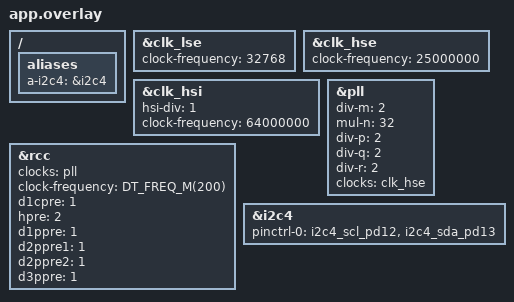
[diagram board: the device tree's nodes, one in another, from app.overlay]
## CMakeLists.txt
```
# SPDX-License-Identifier: Apache-2.0

cmake_minimum_required(VERSION 3.20.0)

find_package(Zephyr REQUIRED HINTS $ENV{ZEPHYR_BASE})
project(hello_world)


include (${CMAKE_SOURCE_DIR}/cmake/functions.cmake)
set(PRE_CONFIGURE_FILE "${CMAKE_CURRENT_SOURCE_DIR}/cmake/git.h.in")
set(POST_CONFIGURE_FILE "${CMAKE_CURRENT_SOURCE_DIR}/git.h")
include (${CMAKE_CURRENT_SOURCE_DIR}/cmake/git_watcher.cmake)
set (CMAKE_CXX_STANDARD 17)


set (PROJ_TOP ${CMAKE_CURRENT_SOURCE_DIR}/../..)

target_sources(app PRIVATE 
	src/uart.c	
	src/main.cpp
	src/pcb9685.cpp
	src/servo.cpp
	src/motor.cpp
	${PROJ_TOP}/robot/comm_protocol/protocol-v1/ProtocolStateMachine.cpp
	${PROJ_TOP}/robot/hal/zephyr/uart_zephyr.cpp
)


target_include_directories(app PRIVATE
	${PROJ_TOP}/comm_protocol/
	${PROJ_TOP}/robot/hal
	${PROJ_TOP}/
	${PROJ_TOP}/robot/comm_protocol/
	${PROJ_TOP}/robot/
	${PROJECT_BINARY_DIR}
	)
```

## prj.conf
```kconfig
# nothing here
#CONFIG_SYS_CLOCK_HW_CYCLES_PER_SEC=192000000
CONFIG_DEBUG=y
CONFIG_STDOUT_CONSOLE=y
CONFIG_NO_OPTIMIZATIONS=y
CONFIG_SERIAL=y
CONFIG_CPLUSPLUS=y
CONFIG_NEWLIB_LIBC_NANO=n
CONFIG_LIB_CPLUSPLUS=y
CONFIG_STDOUT_CONSOLE=y
CONFIG_UART_INTERRUPT_DRIVEN=y
CONFIG_I2C=y
CONFIG_LOG=y
CONFIG_MAIN_STACK_SIZE=8092
```

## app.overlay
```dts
/ {
	aliases {
		a-i2c4  = &i2c4;
	};

};

&clk_lse {
	status = "okay";
	clock-frequency = <32768>;
};

&clk_hse {
	status = "okay";
	clock-frequency = <25000000>;
};

&clk_hsi {
	hsi-div = <1>;
	status = "okay";
	clock-frequency = <64000000>;
};

&pll {
	div-m = <2>;
	mul-n = <32>;
	div-p = <2>;
	div-q = <2>;
	div-r = <2>;
	clocks = <&clk_hse>;
	status = "okay";
};

&rcc {
	clocks = <&pll>;
	clock-frequency = <DT_FREQ_M(200)>;

	d1cpre = <1>;
         hpre = <2>;
         d1ppre = <1>;
         d2ppre1 = <1>;
         d2ppre2 = <1>;
         d3ppre = <1>;
};

&i2c4 {
	pinctrl-0 = <&i2c4_scl_pd12 &i2c4_sda_pd13>;
	pinctrl-names = "default";
	status = "okay";
	/*clock-frequency = <I2C_BITRATE_FAST>;*/
};
```

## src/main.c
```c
/*
 * Copyright (c) 2012-2014 Wind River Systems, Inc.
 *
 * SPDX-License-Identifier: Apache-2.0
 */

#include <zephyr/kernel.h>
#include <zephyr/device.h>
#include <zephyr/devicetree.h>
#include <zephyr/drivers/uart.h>

#include <zephyr/kernel.h>
#include <zephyr/device.h>
#include <zephyr/drivers/gpio.h>
#include <zephyr/sys/printk.h>
#include <zephyr/sys/__assert.h>
#include <string.h>


//#include "robot.h"


/* size of stack area used by each thread */
#define STACKSIZE 1024

/* scheduling priority used by each thread */
#define PRIORITY 7



/* UART device name */
#define UART_DEV_NAME usart3

/* UART buffer */
#define UART_BUF_SIZE 64
static uint8_t uart_buffer[UART_BUF_SIZE];

/* UART device structure */
static const struct  device *uart_dev;

/* UART ISR callback */
static void uart_isr(const struct device *dev, void *user_data)
{
	// ARG_UNUSED(user_data);
	uint8_t recv_data;
	int rx_err;

	while (uart_irq_update(dev) && uart_irq_is_pending(dev)) {
		if (uart_irq_rx_ready(dev)) {
			rx_err = uart_fifo_read(dev, &recv_data, 1);
			if (rx_err == 0) {
				// Process received data
				// ...
			}
		}
	}
}



#define UART_DEVICE_NODE DT_CHOSEN(zephyr_shell_uart)
#define UART_NODE2 DT_ALIAS(single_line_uart2)
#define UART_NODE2a DT_CHOSEN(zephyr_console)

const struct device *const sl_uart1 ;//= DEVICE_DT_GET(UART_NODE2);
const struct device *const sl_uart2 = DEVICE_DT_GET(UART_NODE2a);



// static const struct device *const uart_dev = DEVICE_DT_GET(UART_DEVICE_NODE);


/* Initialize and configure UART */
static int uart_init(void)
{
	uart_dev = DEVICE_DT_GET(UART_NODE2a);

	//   uart_dev = device_get_binding("usart3");
	if (!uart_dev) {
		printk("Failed to get UART device\n");
		return -ENODEV;
	}

	/* Configure UART */
	const struct uart_config uart_cfg = {
		.baudrate = 115200,
		.parity = UART_CFG_PARITY_NONE,
		.stop_bits = UART_CFG_STOP_BITS_1,
		.data_bits = UART_CFG_DATA_BITS_8,
		.flow_ctrl = UART_CFG_FLOW_CTRL_NONE
	};

	int ret = uart_configure(uart_dev, &uart_cfg);
	if (ret != 0) {
		printk("Failed to configure UART: %d\n", ret);
		return ret;
	}

	/* Register UART ISR callback */
	uart_irq_callback_set(uart_dev, uart_isr);

	/* Enable UART interrupt */
	uart_irq_rx_enable(uart_dev);

	printk("UART initialized\n");
	return 0;
}

int main(void)
{
	int ret;

	printk("Zephyr USART Example\n");

	/* Initialize UART */
	ret = uart_init();
	if (ret != 0) {
		printk("UART initialization failed\n");
		return;
	}

	unsigned char recv;
#if 0
	if (/*!device_is_ready(sl_uart1) || */!device_is_ready(sl_uart2)) {
		printk("uart devices not ready\n");
		return 0;
	}
#endif
	char c='a';
	while (true) {
		//uart_poll_out(sl_uart2, c);
		//c++;
		//if (c=='z')
		//	 c='a';
		/* give the uarts some time to get the data through */
		//k_sleep(K_MSEC(50));

		int ret = uart_poll_in(sl_uart2, &c);

		if (ret < 0) {
			//printk("Receiving failed. Error: %d", ret);
		} else {
			uart_poll_out(sl_uart2, c);	
			//	k_sleep(K_MSEC(50));

			//		printk("Received %c\n", recv);
		}

	}
	return 0;

}
```

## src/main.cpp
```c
/*
 * Copyright (c) 2012-2014 Wind River Systems, Inc.
 *
 * SPDX-License-Identifier: Apache-2.0
 */
#include <string.h>
#include <memory>

#include <zephyr/devicetree.h>
#include <zephyr/kernel.h>
#include <zephyr/device.h>
#include <zephyr/drivers/gpio.h>
#include <zephyr/sys/printk.h>
#include <zephyr/sys/__assert.h>
#include <zephyr/drivers/uart.h>
#include <zephyr/drivers/i2c.h>
#include "zephyr/uart_zephyr.h"

#include "protocol-v1/ProtocolStateMachine.h"
#include "protocol-v1/ProtoclDataStructures.h"
#include "HandleUartMsg.h"
#include "robot.h"
#include "pcb9685.h"
#include "motor.h"


/* size of stack area used by each thread */
#define STACKSIZE 8096

/* scheduling priority used by each thread */
#define PRIORITY 7



# if DT_NODE_HAS_STATUS(DT_ALIAS(a_i2c4), okay)
#	define I2C_DEV_NODE	DT_ALIAS(a_i2c4)
# else
#	error "Please set the correct I2C device"
# endif


//const struct device *const sl_uart1 ;//= DEVICE_DT_GET(UART_NODE2);
#define UART_NODE2 DT_CHOSEN(zephyr_console)
const struct device *const sl_uart2 = DEVICE_DT_GET(UART_NODE2);

//uint32_t i2c_cfg = I2C_SPEED_SET(I2C_SPEED_STANDARD) | I2C_MODE_CONTROLLER;
//const struct device *const i2c_dev = DEVICE_DT_GET(I2C_DEV_NODE);
const struct device * const i2c_dev = DEVICE_DT_GET(DT_NODELABEL(i2c4));
//const struct device * i2c_dev = 
// static const struct device *const uart_dev = DEVICE_DT_GET(UART_DEVICE_NODE);


K_MSGQ_DEFINE(sevo_msgq, sizeof(Payload::ServoParams), 16, 4);



pcb9685 * g_pwm = new pcb9685(i2c_dev);
Motor  * g_motor = new Motor(g_pwm, &sevo_msgq);


int main(void)
{
	std::cout << "begin c++ app"<<std::endl;		
	printk("Zephyr USART Example\n");

	while (1) {
		k_sleep(K_MSEC(2000));		
	}


	return 0;

}



double map_angle (int min_pwm, int max_pwm, int angle) {
	double min_ang=0;
	double max_ang=180;
	double pwm = (max_pwm-min_pwm)/(max_ang-min_ang) * angle + min_pwm;
	pwm = pwm /  1000000; // move to uq
	return pwm;	     
}
void servo_command_listenr(void *p1,void *p2, void *p3)
{
	Simple::Payload::ServoParams  servoParams;
	Motor * motor = * ( (Motor **) p1); 

	printk("servo_command_listenr\n");

	motor->setup();
	while (1) {
		if (k_msgq_get(&sevo_msgq, &servoParams, K_FOREVER) == 0) {
			for (int i = 0; i <16; i++) {
				double c = map_angle(servoParams.min_pwm, servoParams.max_pwm , servoParams.angle[i]);
				if (servoParams.update_bit & (1<<i))
					motor->setServoPulse(i,c);
			}
		}
	}
	k_sleep(K_MSEC(2000));			
}

K_THREAD_DEFINE(servo_command_listenr_id, STACKSIZE, servo_command_listenr, &g_motor, NULL, NULL, PRIORITY, 0, 0);



void message_in_listenr(void *p1,void *p2, void *p3)
{
	Motor * motor = *( (Motor **) p1); 
	printk("message_in_listenr\n");

	auto uart = Hal::GetUartZephyr(sl_uart2);
	uart->Open();
	auto p  =  std::shared_ptr<Simple::HandleUartMsg>(new Simple::HandleUartMsg(uart, motor) );
	std::shared_ptr<IProtocolParser> parser = std::shared_ptr<Simple::ProtocolStateMachine> ( new Simple::ProtocolStateMachine  (uart, p));


#if 0
	auto login =  [] () ->void{

	};	
	login();
#endif

	while (1) {
		parser->Parse();
	}
}

K_THREAD_DEFINE(message_in_listenr_id, STACKSIZE, message_in_listenr, &g_motor, NULL, NULL, PRIORITY, 0, 0);
```

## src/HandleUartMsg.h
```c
/*
 * =====================================================================================
 *
 *       Filename:  protocol.h
 *
 *    Description:  
 *
 *        Version:  1.0
 *        Created:  11/11/2022 03:14:53 PM
 *       Revision:  none
 *       Compiler:  gcc
 *
 *        Company:  Israel
 *
 * =====================================================================================
 */

#ifndef PROTOCOL_H
#define PROTOCOL_H 
#include <string>
#include <memory>
#include <vector>

#include <cstring>
#include <type_traits>
#include <utility>

#include "IProtocolParser.h"

#include "protocol-v1/ProtoclDataStructures.h"
#include "protocol-v1/SensorDataParser.h"
#include "protocol-v1/messages.h"
#include "protocol-v1/IHandleUartMsg.h"
#include "common/logger.h"

#include "motor.h"
namespace Simple {

	class HandleUartMsg: public IHandleUartMsg {
		public:
			HandleUartMsg(std::shared_ptr<Hal::IUart> uart, Motor *motor) : m_uart(uart) {
				m_motor = motor;
			}
			void NewData(const MsgToParse &msg) override {
				switch (msg.cmd) {

					case CmdId::GetDeviceInfo:
						{

							DeviceInfo deviceInfo;
							auto msg = deviceInfo();
							///msg->data.hw_version [0] = 1;
							int n = m_uart->Send(msg->buffer,msg->size()); 
							(void)n;

							break;
						}
					case CmdId::SetMotorAngle:
						{	
							Payload::ServoParams *di = (Payload::ServoParams*)(msg.data.buffer);	
							if (m_motor->pushMessage(*di) == 0) {
								Ack ack;
								auto res_msg = ack();
								int n = m_uart->Send(res_msg->buffer,res_msg->size()); 
								(void)n;
							} else {
								NotAck ack;
								auto res_msg = ack();
								int n = m_uart->Send(res_msg->buffer,res_msg->size()); 
								(void)n;
							}
							break;

						}

				}

			};
			void Wrongdata() override {
			};
		private:
			std::shared_ptr<Hal::IUart> m_uart;			
			Motor * m_motor;


	};





}



#endif
```

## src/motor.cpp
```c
/*
 * =====================================================================================
 *
 *       Filename:  motor.cpp
 *
 *    Description:  
 *
 *        Version:  1.0
 *        Created:  07/11/2023 10:58:14 PM
 *       Revision:  none
 *       Compiler:  gcc
 *
 *         Author:  Yair Gadelov (yg), yair.gadelov@gmail.com
 *        Company:  Israel
 *
 * =====================================================================================
 */

#include "motor.h"
#define SERVOMIN  150 // This is the 'minimum' pulse length count (out of 4096)
#define SERVOMAX  600 // This is the 'maximum' pulse length count (out of 4096)
#define USMIN  600 // This is the rounded 'minimum' microsecond length based on the minimum pulse of 150
#define USMAX  2400 // This is the rounded 'maximum' microsecond length based on the maximum pulse of 600
#define SERVO_FREQ 50 // Analog servos run at ~50 Hz updates
#define delay(x) k_sleep(K_MSEC(x))


void Motor::setServoPulse( uint8_t n, double pulse) {
  double pulselength;
  
  pulselength = 1000000;   // 1,000,000 us per second
  pulselength /= SERVO_FREQ;   // Analog servos run at ~60 Hz updates
  //Serial.print(pulselength); Serial.println(" us per period"); 
  pulselength /= 4096;  // 12 bits of resolution
 // Serial.print(pulselength); Serial.println(" us per bit"); 
  pulse *= 1000000;  // convert input seconds to us
  pulse /= pulselength;
//  Serial.println(pulse);
  m_pwm->setPWM(n, 0, pulse);
}


void Motor::setup() {
  m_pwm->begin();
  /*
   * In theory the internal oscillator (clock) is 25MHz but it really isn't
   * that precise. You can 'calibrate' this by tweaking this number until
   * you get the PWM update frequency you're expecting!
   * The int.osc. for the PCA9685 chip is a range between about 23-27MHz and
   * is used for calculating things like writeMicroseconds()
   * Analog servos run at ~50 Hz updates, It is importaint to use an
   * oscilloscope in setting the int.osc frequency for the I2C PCA9685 chip.
   * 1) Attach the oscilloscope to one of the PWM signal pins and ground on
   *    the I2C PCA9685 chip you are setting the value for.
   * 2) Adjust setOscillatorFrequency() until the PWM update frequency is the
   *    expected value (50Hz for most ESCs)
   * Setting the value here is specific to each individual I2C PCA9685 chip and
   * affects the calculations for the PWM update frequency. 
   * Failure to correctly set the int.osc value will cause unexpected PWM results
   */
//  pwm->setOscillatorFrequency(27000000);
  m_pwm->setPWMFreq(SERVO_FREQ);  // Analog servos run at ~50 Hz updates
}
```

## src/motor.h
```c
/*
 * =====================================================================================
 *
 *       Filename:  motor.h
 *
 *    Description:  
 *
 *        Version:  1.0
 *        Created:  07/11/2023 10:58:26 PM
 *       Revision:  none
 *       Compiler:  gcc
 *
 *         Author:  Yair Gadelov (yg), yair.gadelov@gmail.com
 *        Company:  Israel
 *
 * =====================================================================================
 */

#ifndef MOTOR_H
#define MOTOR_H 
#include "pcb9685.h"
#include <zephyr/kernel.h>
#include "protocol-v1/ProtoclDataStructures.h"

class Motor {
	public:
		Motor(pcb9685 * pwm, k_msgq * msgq) : m_pwm(pwm) {
			m_msgq = msgq;
		}
		void setServoPulse(uint8_t n, double pulse);
		int pushMessage(Simple::Payload::ServoParams  & motorAngle) {
			int e = k_msgq_put(m_msgq, &motorAngle, K_NO_WAIT);
			return e;
		}
		void setup();
		
	private:
		pcb9685  * m_pwm;
		k_msgq * m_msgq;
};
#endif
```

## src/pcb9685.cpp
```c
/*
 * =====================================================================================
 *
 *       Filename:  pcb9685.h
 *
 *    Description:  driver for pca9685. Taken from arduino imelemnation here:
 *    https://github.com/adafruit/Adafruit-PWM-Servo-Driver-Library/blob/master/Adafruit_PWMServoDriver.cpp#L222
 *
 *        Version:  1.0
 *        Created:  07/02/2023 12:23:34 PM
 *       Revision:  none
 *       Compiler:  gcc
 *
 *         Author:  Yair Gadelov (yg), yair.gadelov@gmail.com
 *        Company:  Israel
 *
 * =====================================================================================
 */

#include "pcb9685.h"
#include <zephyr/kernel.h>
#include <memory>
#include <iostream>
#define delay(x) k_sleep(K_MSEC(x))

#define ENABLE_DEBUG_OUTPUT




/*!
 *  @brief  Setups the I2C interface and hardware
 *  @param  prescale
 *          Sets External Clock (Optional)
 *  @return true if successful, otherwise false
 */
bool pcb9685::begin(uint8_t prescale) {
  reset();
  if (prescale) {
    setExtClk(prescale);
  } else {
    // set a default frequency
    setPWMFreq(1000);
  }
  // set the default internal frequency
  setOscillatorFrequency(FREQUENCY_OSCILLATOR);

  return true;
}

/*!
 *  @brief  Sends a reset command to the PCA9685 chip over I2C
 */
void pcb9685::reset() {
  write8(PCA9685_MODE1, MODE1_RESTART);
  delay(10);
}

/*!
 *  @brief  Puts board into sleep mode
 */
void pcb9685::sleep() {
  uint8_t awake = read8(PCA9685_MODE1);
  uint8_t sleep = awake | MODE1_SLEEP; // set sleep bit high
  write8(PCA9685_MODE1, sleep);
  delay(5); // wait until cycle ends for sleep to be active
}

/*!
 *  @brief  Wakes board from sleep
 */
void pcb9685::wakeup() {
  uint8_t sleep = read8(PCA9685_MODE1);
  uint8_t wakeup = sleep & ~MODE1_SLEEP; // set sleep bit low
  write8(PCA9685_MODE1, wakeup);
}

/*!
 *  @brief  Sets EXTCLK pin to use the external clock
 *  @param  prescale
 *          Configures the prescale value to be used by the external clock
 */
void pcb9685::setExtClk(uint8_t prescale) {
  uint8_t oldmode = read8(PCA9685_MODE1);
  uint8_t newmode = (oldmode & ~MODE1_RESTART) | MODE1_SLEEP; // sleep
  write8(PCA9685_MODE1, newmode); // go to sleep, turn off internal oscillator

  // This sets both the SLEEP and EXTCLK bits of the MODE1 register to switch to
  // use the external clock.
  write8(PCA9685_MODE1, (newmode |= MODE1_EXTCLK));

  write8(PCA9685_PRESCALE, prescale); // set the prescaler

  delay(5);
  // clear the SLEEP bit to start
  write8(PCA9685_MODE1, (newmode & ~MODE1_SLEEP) | MODE1_RESTART | MODE1_AI);

#ifdef ENABLE_DEBUG_OUTPUT
  //printk("Mode now 0x");
//  printk("%d %x \n",read8(PCA9685_MODE1), HEX);
#endif
}

/*!
 *  @brief  Sets the PWM frequency for the entire chip, up to ~1.6 KHz
 *  @param  freq Floating point frequency that we will attempt to match
 */
void pcb9685::setPWMFreq(float freq) {
#ifdef ENABLE_DEBUG_OUTPUT
  printk("Attempting to set freq ");
  printk("%lf \n",freq);
#endif
  // Range output modulation frequency is dependant on oscillator
  if (freq < 1)
    freq = 1;
  if (freq > 3500)
    freq = 3500; // Datasheet limit is 3052=50MHz/(4*4096)

  float prescaleval = ((_oscillator_freq / (freq * 4096.0)) + 0.5) - 1;
  if (prescaleval < PCA9685_PRESCALE_MIN)
    prescaleval = PCA9685_PRESCALE_MIN;
  if (prescaleval > PCA9685_PRESCALE_MAX)
    prescaleval = PCA9685_PRESCALE_MAX;
  uint8_t prescale = (uint8_t)prescaleval;

#ifdef ENABLE_DEBUG_OUTPUT
  printk("Final pre-scale: ");
  printk("%d \n",prescale);
#endif

  uint8_t oldmode = read8(PCA9685_MODE1);
  uint8_t newmode = (oldmode & ~MODE1_RESTART) | MODE1_SLEEP; // sleep
  write8(PCA9685_MODE1, newmode);                             // go to sleep
  write8(PCA9685_PRESCALE, prescale); // set the prescaler
  write8(PCA9685_MODE1, oldmode);
  delay(5);
  // This sets the MODE1 register to turn on auto increment.
  write8(PCA9685_MODE1, oldmode | MODE1_RESTART | MODE1_AI);

#ifdef ENABLE_DEBUG_OUTPUT
 // printk("Mode now 0x");
  //printk("%d %x\n",read8(PCA9685_MODE1), HEX);
#endif
}

/*!
 *  @brief  Sets the output mode of the PCA9685 to either
 *  open drain or push pull / totempole.
 *  Warning: LEDs with integrated zener diodes should
 *  only be driven in open drain mode.
 *  @param  totempole Totempole if true, open drain if false.
 */
void pcb9685::setOutputMode(bool totempole) {
  uint8_t oldmode = read8(PCA9685_MODE2);
  uint8_t newmode;
  if (totempole) {
    newmode = oldmode | MODE2_OUTDRV;
  } else {
    newmode = oldmode & ~MODE2_OUTDRV;
  }
  write8(PCA9685_MODE2, newmode);
#ifdef ENABLE_DEBUG_OUTPUT
  printk("Setting output mode: ");
  printk(totempole ? "totempole" : "open drain");
  printk(" by setting MODE2 to ");
  printk("%d ",newmode);
#endif
}

/*!
 *  @brief  Reads set Prescale from PCA9685
 *  @return prescale value
 */
uint8_t pcb9685::readPrescale(void) {
  return read8(PCA9685_PRESCALE);
}

/*!
 *  @brief  Gets the PWM output of one of the PCA9685 pins
 *  @param  num One of the PWM output pins, from 0 to 15
 *  @param  off If true, returns PWM OFF value, otherwise PWM ON
 *  @return requested PWM output value
 */
uint16_t pcb9685::getPWM(uint8_t num, bool off) {
  uint8_t buffer[2] = {uint8_t(PCA9685_LED0_ON_L + 4 * num), 0};
  if (off)
    buffer[0] += 2;
  	i2c_write_read (m_i2c_dev, PCA9685_I2C_ADDRESS,buffer, 1 , buffer, 2);
	//  i2c_dev->write_then_read(buffer, 1, buffer, 2);
  return uint16_t(buffer[0]) | (uint16_t(buffer[1]) << 8);
}

/*!
 *  @brief  Sets the PWM output of one of the PCA9685 pins
 *  @param  num One of the PWM output pins, from 0 to 15
 *  @param  on At what point in the 4096-part cycle to turn the PWM output ON
 *  @param  off At what point in the 4096-part cycle to turn the PWM output OFF
 *  @return result from endTransmission
 */
uint8_t pcb9685::setPWM(uint8_t num, uint16_t on,
                                        uint16_t off) {
#ifdef ENABLE_DEBUG_OUTPUT
  printk("Setting PWM ");
  printk("%d ",num);
  printk(": ");
  printk("%d ",on);
  printk("->");
  printk("%d\n",off);
#endif

  uint8_t buffer[5];
  buffer[0] = PCA9685_LED0_ON_L + 4 * num;
  buffer[1] = on;
  buffer[2] = on >> 8;
  buffer[3] = off;
  buffer[4] = off >> 8;
  i2c_write(m_i2c_dev, buffer, 5, PCA9685_I2C_ADDRESS);
  
  //i2c_dev->write(buffer, 5);

  return 0;
}

/*!
 *   @brief  Helper to set pin PWM output. Sets pin without having to deal with
 * on/off tick placement and properly handles a zero value as completely off and
 * 4095 as completely on.  Optional invert parameter supports inverting the
 * pulse for sinking to ground.
 *   @param  num One of the PWM output pins, from 0 to 15
 *   @param  val The number of ticks out of 4096 to be active, should be a value
 * from 0 to 4095 inclusive.
 *   @param  invert If true, inverts the output, defaults to 'false'
 */
void pcb9685::setPin(uint8_t num, uint16_t val, bool invert) {
  // Clamp value between 0 and 4095 inclusive.
  val = MIN(val, (uint16_t)4095);
  if (invert) {
    if (val == 0) {
      // Special value for signal fully on.
      setPWM(num, 4096, 0);
    } else if (val == 4095) {
      // Special value for signal fully off.
      setPWM(num, 0, 4096);
    } else {
      setPWM(num, 0, 4095 - val);
    }
  } else {
    if (val == 4095) {
      // Special value for signal fully on.
      setPWM(num, 4096, 0);
    } else if (val == 0) {
      // Special value for signal fully off.
      setPWM(num, 0, 4096);
    } else {
      setPWM(num, 0, val);
    }
  }
}

/*!
 *  @brief  Sets the PWM output of one of the PCA9685 pins based on the input
 * microseconds, output is not precise
 *  @param  num One of the PWM output pins, from 0 to 15
 *  @param  Microseconds The number of Microseconds to turn the PWM output ON
 */
void pcb9685::writeMicroseconds(uint8_t num,
                                                uint16_t Microseconds) {
#ifdef ENABLE_DEBUG_OUTPUT
  printk("Setting PWM Via Microseconds on output");
  printk("%d", num);
  printk(": ");
  printk("%d",Microseconds);
  printk("->\n");
#endif

  double pulse = Microseconds;
  double pulselength;
  pulselength = 1000000; // 1,000,000 us per second

  // Read prescale
  uint16_t prescale = readPrescale();

#ifdef ENABLE_DEBUG_OUTPUT
  printk("%d ",prescale);
  printk(" PCA9685 chip prescale\n");
#endif

  // Calculate the pulse for PWM based on Equation 1 from the datasheet section
  // 7.3.5
  prescale += 1;
  pulselength *= prescale;
  pulselength /= _oscillator_freq;

#ifdef ENABLE_DEBUG_OUTPUT
  printk("%f  us per bit\n", pulselength);
#endif

  pulse /= pulselength;

#ifdef ENABLE_DEBUG_OUTPUT
  printk("%f pulse for PWM\n", pulse);
#endif

  setPWM(num, 0, pulse);
}

/*!
 *  @brief  Getter for the internally tracked oscillator used for freq
 * calculations
 *  @returns The frequency the PCA9685 thinks it is running at (it cannot
 * introspect)
 */
uint32_t pcb9685::getOscillatorFrequency(void) {
  return _oscillator_freq;
}

/*!
 *  @brief Setter for the internally tracked oscillator used for freq
 * calculations
 *  @param freq The frequency the PCA9685 should use for frequency calculations
 */
void pcb9685::setOscillatorFrequency(uint32_t freq) {
  _oscillator_freq = freq;
}

/******************* Low level I2C interface */
uint8_t pcb9685::read8(uint8_t addr) {
  uint8_t buffer[1] = {addr};
  	i2c_write_read (m_i2c_dev, PCA9685_I2C_ADDRESS,buffer, 1 , buffer, 1);
	//if (buffer[0]!=0)
	//	printf("%d\n",buffer[0]);

//  i2c_dev->write_then_read(buffer, 1, buffer, 1);
  return buffer[0];
}

void pcb9685::write8(uint8_t addr, uint8_t d) {
  uint8_t buffer[2] = {addr, d};
  i2c_write(m_i2c_dev, buffer, 2, PCA9685_I2C_ADDRESS);
}
```

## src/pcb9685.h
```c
/*
 * =====================================================================================
 *
 *       Filename:  pcb9685.h
 *
 *    Description:  driver for pca9685. Taken from arduino imelemnation here:
 *    https://github.com/adafruit/Adafruit-PWM-Servo-Driver-Library/blob/master/Adafruit_PWMServoDriver.h 
 *        
 *
 *        Version:  1.0
 *        Created:  07/02/2023 12:25:23 PM
 *       Revision:  none
 *       Compiler:  gcc
 *
 *         Author:  Yair Gadelov (yg), yair.gadelov@gmail.com
 *        Company:  Israel
 *
 * =====================================================================================
 */

#ifndef _ADAFRUIT_PWMServoDriver_H
#define _ADAFRUIT_PWMServoDriver_H
#include <stdint.h>
#include <zephyr/drivers/i2c.h>



// REGISTER ADDRESSES
#define PCA9685_MODE1 0x00      /**< Mode Register 1 */
#define PCA9685_MODE2 0x01      /**< Mode Register 2 */
#define PCA9685_SUBADR1 0x02    /**< I2C-bus subaddress 1 */
#define PCA9685_SUBADR2 0x03    /**< I2C-bus subaddress 2 */
#define PCA9685_SUBADR3 0x04    /**< I2C-bus subaddress 3 */
#define PCA9685_ALLCALLADR 0x05 /**< LED All Call I2C-bus address */
#define PCA9685_LED0_ON_L 0x06  /**< LED0 on tick, low byte*/
#define PCA9685_LED0_ON_H 0x07  /**< LED0 on tick, high byte*/
#define PCA9685_LED0_OFF_L 0x08 /**< LED0 off tick, low byte */
#define PCA9685_LED0_OFF_H 0x09 /**< LED0 off tick, high byte */
// etc all 16:  LED15_OFF_H 0x45
#define PCA9685_ALLLED_ON_L 0xFA  /**< load all the LEDn_ON registers, low */
#define PCA9685_ALLLED_ON_H 0xFB  /**< load all the LEDn_ON registers, high */
#define PCA9685_ALLLED_OFF_L 0xFC /**< load all the LEDn_OFF registers, low */
#define PCA9685_ALLLED_OFF_H 0xFD /**< load all the LEDn_OFF registers,high */
#define PCA9685_PRESCALE 0xFE     /**< Prescaler for PWM output frequency */
#define PCA9685_TESTMODE 0xFF     /**< defines the test mode to be entered */

// MODE1 bits
#define MODE1_ALLCAL 0x01  /**< respond to LED All Call I2C-bus address */
#define MODE1_SUB3 0x02    /**< respond to I2C-bus subaddress 3 */
#define MODE1_SUB2 0x04    /**< respond to I2C-bus subaddress 2 */
#define MODE1_SUB1 0x08    /**< respond to I2C-bus subaddress 1 */
#define MODE1_SLEEP 0x10   /**< Low power mode. Oscillator off */
#define MODE1_AI 0x20      /**< Auto-Increment enabled */
#define MODE1_EXTCLK 0x40  /**< Use EXTCLK pin clock */
#define MODE1_RESTART 0x80 /**< Restart enabled */
// MODE2 bits
#define MODE2_OUTNE_0 0x01 /**< Active LOW output enable input */
#define MODE2_OUTNE_1 0x02 /**< Active LOW output enable input - high impedience */
#define MODE2_OUTDRV 0x04 /**< totem pole structure vs open-drain */
#define MODE2_OCH 0x08    /**< Outputs change on ACK vs STOP */
#define MODE2_INVRT 0x10  /**< Output logic state inverted */

#define PCA9685_I2C_ADDRESS 0x40      /**< Default PCA9685 I2C Slave Address */
#define FREQUENCY_OSCILLATOR 25000000 /**< Int. osc. frequency in datasheet */

#define PCA9685_PRESCALE_MIN 3   /**< minimum prescale value */
#define PCA9685_PRESCALE_MAX 255 /**< maximum prescale value */

/*!
 *  @brief  Class that stores state and functions for interacting with PCA9685
 * PWM chip
 */
class pcb9685 {
	public:
		pcb9685(const struct device * device)   {
			m_i2c_dev = 0;
			if (device && !device_is_ready(device)) {
				m_i2c_dev = 0;
			}
			m_i2c_dev = device;


		};  
		bool begin(uint8_t prescale = 0);
		void reset();
		void sleep();
		void wakeup();
		void setExtClk(uint8_t prescale);
		void setPWMFreq(float freq);
		void setOutputMode(bool totempole);
		uint16_t getPWM(uint8_t num, bool off = false);
		uint8_t setPWM(uint8_t num, uint16_t on, uint16_t off);
		void setPin(uint8_t num, uint16_t val, bool invert = false);
		uint8_t readPrescale(void);
		void writeMicroseconds(uint8_t num, uint16_t Microseconds);

		void setOscillatorFrequency(uint32_t freq);
		uint32_t getOscillatorFrequency(void);

	private:

		uint32_t _oscillator_freq;
		uint8_t read8(uint8_t addr);
		void write8(uint8_t addr, uint8_t d);
		const struct device * m_i2c_dev;
};
#endif
```
